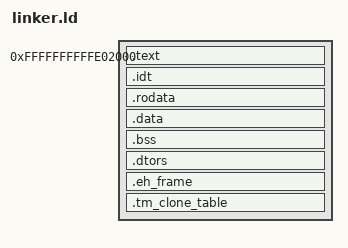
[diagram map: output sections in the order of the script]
mmio        = 0xfffffffff8000000;              /* these are configurable for level 2 loaders */
fb          = 0xfffffffffc000000;
bootboot    = 0xffffffffffe00000;
environment = 0xffffffffffe01000;



/* The bootloader will look at this image and start execution at the symbol
   designated at the entry point. */
ENTRY(_start)

/* Tell where the various sections of the object files will be put in the final
   kernel image. */
SECTIONS {
	/* Begin putting sections at 1 MiB, a conventional place for kernels to be
	   loaded at by the bootloader. */
	. = 0xffffffffffe02000;

	/* First put the multiboot header, as it is required to be put very early
	   early in the image or the bootloader won't recognize the file format.
	   Next we'll put the .text section. */
	.text BLOCK(4K) : ALIGN(4K) {
		*(.multiboot)
		*(.text)
	}

	.idt BLOCK(4K) : ALIGN(4K) {
		_idt = .;
		. = . + 4K;
	}
	/* Read-only data. */
	.rodata BLOCK(4K) : ALIGN(4K) {
		*(.rodata)
	}

	/* Read-write data (initialized) */
	.data BLOCK(4K) : ALIGN(4K) {
		*(.data)
	}

	/* Read-write data (uninitialized) and stack */
	.bss BLOCK(4K) : ALIGN(4K) {
		*(COMMON)
		*(.bss)
	}

	.dtors BLOCK(4K) : ALIGN(4K) {
		*(.dtors)
	}
	.eh_frame BLOCK(4K) : ALIGN(4K) {
		*(.eh_frame)
	}

	.tm_clone_table BLOCK(4K) : ALIGN(4K) {
		*(.tm_clone_table)
	}
	
	/* The compiler may produce other sections, put them in the proper place in
	   in this file, if you'd like to include them in the final kernel. */

	/DISCARD/ : {
		*(.comment)
	}
}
